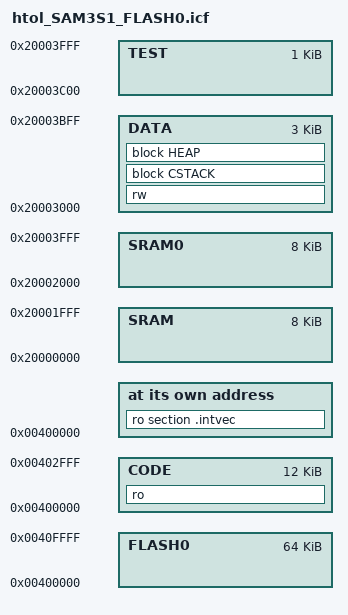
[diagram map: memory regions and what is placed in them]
/*###ICF### Section handled by ICF editor, don't touch! ****/
/*-Editor annotation file-*/
/* IcfEditorFile="$TOOLKIT_DIR$\config\ide\IcfEditor\a_v1_0.xml" */
/*-Specials-*/
define symbol __ICFEDIT_intvec_start__ = 0x00400000;
/*-Memory Regions-*/

define symbol __ICFEDIT_region_FLASH0_start__ = 0x00400000;
define symbol __ICFEDIT_region_FLASH0_size__  = 0x10000;
define symbol __ICFEDIT_region_SRAM_start__   = 0x20000000;
define symbol __ICFEDIT_region_SRAM_size__    = 0x2000;
define symbol __ICFEDIT_region_SRAM0_start__  = 0x20002000;
define symbol __ICFEDIT_region_SRAM0_size__   = 0x2000;

define symbol __ICFEDIT_region_CODE_start__  = 0x00400000;
define symbol __ICFEDIT_region_CODE_size__   = 0x3000;
define symbol __ICFEDIT_region_DATA_start__  = 0x20003000;
define symbol __ICFEDIT_region_DATA_size__   = 0x0C00;
define symbol __ICFEDIT_region_TEST_start__  = 0x20003C00;
define symbol __ICFEDIT_region_TEST_size__   = 0x400;



/*-Sizes-*/
define symbol __ICFEDIT_size_cstack__   = 0x0400;
define symbol __ICFEDIT_size_heap__     = 0x0100;
/**** End of ICF editor section. ###ICF###*/


define memory mem with size = 4G;
define region FLASH0 = mem:[from __ICFEDIT_region_FLASH0_start__ size __ICFEDIT_region_FLASH0_size__];
define region SRAM   = mem:[from __ICFEDIT_region_SRAM_start__   size __ICFEDIT_region_SRAM_size__];
define region SRAM0  = mem:[from __ICFEDIT_region_SRAM0_start__  size __ICFEDIT_region_SRAM0_size__];
define region CODE   = mem:[from __ICFEDIT_region_CODE_start__   size __ICFEDIT_region_CODE_size__];
define region DATA   = mem:[from __ICFEDIT_region_DATA_start__   size __ICFEDIT_region_DATA_size__];
define region TEST   = mem:[from __ICFEDIT_region_TEST_start__   size __ICFEDIT_region_TEST_size__];

define block CSTACK    with alignment = 4, size = __ICFEDIT_size_cstack__   { };
define block HEAP      with alignment = 4, size = __ICFEDIT_size_heap__     { };

initialize by copy { rw };
do not initialize  { section .noinit };


place at address mem:__ICFEDIT_intvec_start__ { ro section .intvec };

place in CODE  { ro  };
place in DATA  { rw , block CSTACK, block HEAP };
                        
